# NUC122_v1 register map
File version: 1.0
Registers are 32-bit, read-write, reset 0x0 unless marked. A register's access mark holds for its fields unless they carry their own. Offsets are from the block's base; [hi:lo] are bit positions; 'fields as' and 'values as' point back to an identical list.

## SPI0 — SPI Register Map
Base 0x40030000
Same registers: SPI1 0x40034000
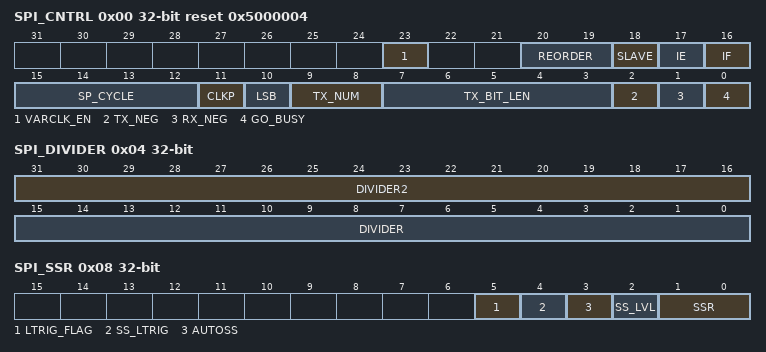
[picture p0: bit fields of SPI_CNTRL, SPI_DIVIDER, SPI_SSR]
0x00 SPI_CNTRL reset 0x5000004 — Control and Status Register
  [23] VARCLK_EN — Variable Clock Enable (Master only). Note that when enable this VARCLK_EN bit, the setting of TX_BIT_LEN must be programmed as 0x10 (16 bits mode)
    0=The serial clock output frequency is fixed and decided only by the value of DIVIDER; 1=The serial clock output frequency is variable. The output frequency is decided by the value of VARCLK, DIVIDER, and DIVIDER2
  [20:19] REORDER — Reorder Mode Select. Note: 1. Byte reorder function is only available if TX_BIT_LEN is defined as 16, 24, and 32 bits. 2. In slave mode with level-trigger configuration, if the byte suspend function is enabled, the slave select pin must be kept at active state during the successive four bytes transfer.
    0=Disable both byte reorder and byte suspend functions; 1=Enable byte reorder function and insert a byte suspend interval (2~17 SPICLK cycles) among each byte. The setting of TX_BIT_LEN must be configured as 0x00. (32 bits/word); 2=Enable byte reorder function, but disable byte suspend function; 3=Disable byte reorder function, but insert a suspend interval (2~17 SPICLK cycles) among each byte. The setting of TX_BIT_LEN must be configured as 0x00. (32 bits/word)
  [18] SLAVE — Slave Mode Indication
    0=Master mode; 1=Slave mode
  [17] IE — Interrupt Enable
    0=Disable SPI Interrupt; 1=Enable SPI Interrupt
  [16] IF — Interrupt Flag. Note: This bit is cleared by writing 1 to itself.
    0=It indicates that the transfer dose not finish yet; 1=It indicates that the transfer is done
  [15:12] SP_CYCLE — Suspend Interval (Master only)
  [11] CLKP — Clock Polarity
    0=SPICLK idle low; 1=SPICLK idle high
  [10] LSB — LSB First
    0=The MSB is transmitted/received first (which bit in SPI_TX0/1 and SPI_RX0/1 register that is depends on the TX_BIT_LEN field); 1=The LSB is sent first on the line (bit 0 of SPI_TX0/1), and the first bit received from the line will be put in the LSB position in the RX register (bit 0 of SPI_RX0/1)
  [9:8] TX_NUM — Numbers of Transmit/Receive Word. This field specifies how many transmit/receive word numbers should be executed in one transfer. Note: In slave mode with level-trigger configuration, if TX_NUM is set to 01, the slave select pin must be kept at active state during the successive data transfer.
    0=Only one transmit/receive word will be executed in one transfer; 1=Two successive transmit/receive words will be executed in one transfer. (burst mode)
  [7:3] TX_BIT_LEN — Transmit Bit Length. This field specifies how many bits are transmitted in one transaction. Up to 32 bits can be transmitted.
  [2] TX_NEG — Transmit At Negative Edge
    0=The transmitted data output signal is changed at the rising edge of SPICLK; 1=The transmitted data output signal is changed at the falling edge of SPICLK
  [1] RX_NEG — Receive At Negative Edge
    0=The received data input signal is latched at the rising edge of SPICLK; 1=The received data input signal is latched at the falling edge of SPICLK
  [0] GO_BUSY — Go and Busy Status. During the data transfer, this bit keeps the value of 1. As the transfer is finished, this bit will be cleared automatically. Note: All registers should be set before writing 1 to this GO_BUSY bit.
    0=Writing 0 to this bit to stop data transfer if SPI is transferring; 1=In master mode, writing 1 to this bit to start the SPI data transfer; in slave mode, writing 1 to this bit indicates that the slave is ready to communicate with a master
0x04 SPI_DIVIDER — Clock Divider Register (Master only)
  [31:16] DIVIDER2 — Clock Divider 2 Register (Master only). The value in this field is the 2nd frequency divider for generating the serial clock on the output SPICLK. The desired frequency is obtained according to the following equation: . If VARCLK_EN is cleared to 0, this setting is unmeaning.
  [15:0] DIVIDER — Clock Divider Register (Master only). The value in this field is the frequency divider for generating the serial clock on the output SPICLK. The desired frequency is obtained according to the following equation: . In slave mode, the period of SPI clock driven by a master shall equal or over 5 times the period of PCLK. In other words, the maximum frequency of SPI clock is the fifth of the frequency of slave's PCLK.
0x08 SPI_SSR — Slave Select Register
  [5] LTRIG_FLAG — Level Trigger Flag. When the SS_LTRIG bit is set in slave mode, this bit can be read to indicate the received bit number is met the requirement or not. Note: This bit is READ only
    0=The transaction number or the transferred bit length of one transaction doesn't meet the specified requirements; 1=The transaction number and the transferred bit length met the specified requirements which defined in TX_NUM and TX_BIT_LEN
  [4] SS_LTRIG — Slave Select Level Trigger (Slave only)
    0=The input slave select signal is edge-trigger. This is the default value. It depends on SS_LVL to decide the signal is active at falling-edge or rising-edge; 1=The slave select signal will be level-trigger. It depends on SS_LVL to decide the signal is active low or active high
  [3] AUTOSS — Automatic Slave Select (Master only)
    0=If this bit is cleared, slave select signals will be asserted and de-asserted by setting and clearing related bits in SSR[1:0]; 1=If this bit is set, SPISSx0/1 signals will be generated automatically. It means that device/slave select signal, which is set in SSR[1:0], will be asserted by the SPI controller when transmit/receive is started by setting GO_BUSY, and will be de-asserted after each transmit/receive is finished
  [2] SS_LVL — Slave Select Active Level. It defines the active state of slave select signal (SPISSx0/1).
    0=The slave select signal SPISSx0/1 is active at low-level/falling-edge; 1=The slave select signal SPISSx0/1 is active at high-level/rising-edge
  [1:0] SSR — Slave Select Register (Master only). If AUTOSS bit is cleared, writing 1 to any bit location of this field sets the proper SPISSx0/1 line to an active state and writing 0 sets the line back to inactive state. If AUTOSS bit is set, writing 0 to any bit location of this field will keep the corresponding SPISSx0/1 line at inactive state; writing 1 to any bit location of this field will select the corresponding SPISSx0/1 line to be automatically driven to active state for the duration of the transmit/receive, and will be driven to inactive state for the rest of the time. The active state of SPISSx0/1 is specified in SS_LVL. Note: SPISSx0 is also defined as slave select input in slave mode.
0x10 SPI_RX0 ro — Data Receive Register 0
  [31:0] RX — Data Receive Register. The Data Receive Registers hold the value of received data of the last executed transfer. Valid bits depend on the transmit bit length field in the SPI_CNTRL register. For example, if TX_BIT_LEN is set to 0x08 and TX_NUM is set to 0x0, bit RX0[7:0] holds the received data. The values of the other bits are unknown. Note: The Data Receive Registers are read only registers.
0x14 SPI_RX1 ro — Data Receive Register 1
  fields as SPI_RX0
0x20 SPI_TX0 wo — Data Transmit Register 0
  [31:0] TX — Data Transmit Register. The Data Transmit Registers hold the data to be transmitted in the next transfer. Valid bits depend on the transmit bit length field in the CNTRL register. For example, if TX_BIT_LEN is set to 0x08 and the TX_NUM is set to 0x0, the bit TX0[7:0] will be transmitted in next transfer. If TX_BIT_LEN is set to 0x00 and TX_NUM is set to 0x1, the SPI controller will perform two 32-bit transmit/receive successive using the same setting. The transmission sequence is TX0[31:0] first and then TX1[31:0].
0x24 SPI_TX1 wo — Data Transmit Register 1
  fields as SPI_TX0
0x34 SPI_VARCLK reset 0x7FFF87 — Variable Clock Pattern Register (Master only)
  [31:0] VARCLK — Variable Clock Pattern (Master only). The value in this field is the frequency patterns of the SPI clock. If the bit pattern of VARCLK is '0', the output frequency of SPICLK is according the value of DIVIDER. If the bit patterns of VARCLK are '1', the output frequency of SPICLK is according the value of DIVIDER2. Refer to register SPI_DIVIDER. Refer to Variable Clock paragraph for more detailed Description.
